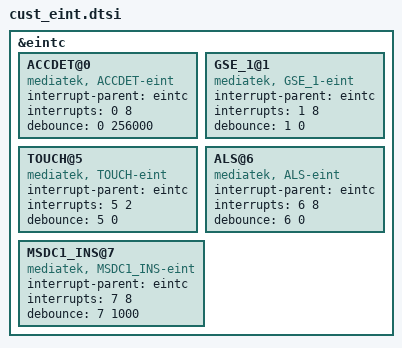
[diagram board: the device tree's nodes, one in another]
/*
 * Generated by MTK SP DrvGen Version 03.13.6 for MT6580. Copyright MediaTek Inc. (C) 2013.
 * Thu Oct 04 05:26:50 2018
 * Do Not Modify the File.
 */

/*************************
 * EINT DTSI File
*************************/

&eintc {
	ACCDET@0 {
		compatible = "mediatek, ACCDET-eint";
		interrupt-parent = <&eintc>;
		interrupts = <0 8>;
		debounce = <0 256000>;
	};

	GSE_1@1 {
		compatible = "mediatek, GSE_1-eint";
		interrupt-parent = <&eintc>;
		interrupts = <1 8>;
		debounce = <1 0>;
	};

	TOUCH@5 {
		compatible = "mediatek, TOUCH-eint";
		interrupt-parent = <&eintc>;
		interrupts = <5 2>;
		debounce = <5 0>;
	};

	ALS@6 {
		compatible = "mediatek, ALS-eint";
		interrupt-parent = <&eintc>;
		interrupts = <6 8>;
		debounce = <6 0>;
	};

	MSDC1_INS@7 {
		compatible = "mediatek, MSDC1_INS-eint";
		interrupt-parent = <&eintc>;
		interrupts = <7 8>;
		debounce = <7 1000>;
	};

};
